# S1C31D50 register map
Vendor: Epson; Series: S1C31D50; File version: 1.00
CPU: CM0PLUS r0p1, little endian, MPU, no FPU, VTOR, 2 interrupt priority bits
Registers are 16-bit, read-write, reset 0x0 unless marked. A register's access mark holds for its fields unless they carry their own. Offsets are from the block's base; [hi:lo] are bit positions; {n}, {i} and the like mark numbered series; 'fields as' and 'values as' point back to an identical list.

## UART3_0 — UART3 channel 0 control
Base 0x00200380
Same registers: UART3_1 0x00200600, UART3_2 0x00200620
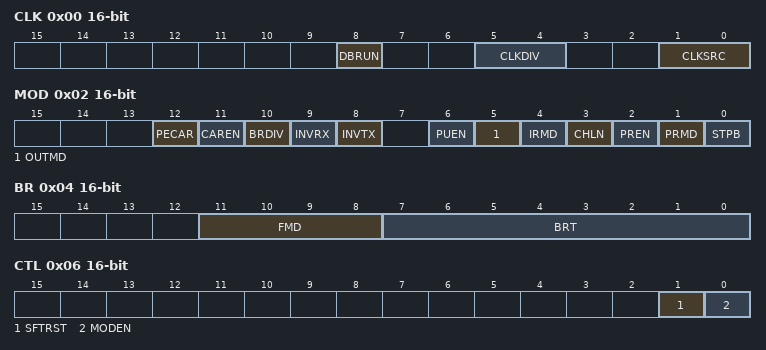
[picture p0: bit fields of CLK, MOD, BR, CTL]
0x00 CLK — Clock Control Register
  [8] DBRUN — Enable clock on debug mode
    0=DISABLE; 1=ENABLE
  [5:4] CLKDIV — Clock division select
  [1:0] CLKSRC — Clock source select
    0=IOSC; 1=OSC1; 2=OSC3; 3=EXOSC
0x02 MOD — Mode Register
  [12] PECAR — Carrier Modulation Period
    0=L_LEVEL (Carrier modulation during L data period); 1=H_LEVEL (Carrier modulation during H data period)
  [11] CAREN — Carrier Modulation Enable
    0=DISABLE (Disable carrier modulation function); 1=ENABLE (Enable carrier modulation function)
  [10] BRDIV — Baud Rate Division ratio
    0=DIV_1_16 (Ratio 1 over 16); 1=DIV_1_4 (Ratio 1 over 4)
  [9] INVRX — Invert receive signal
    0=DISABLE (Disable input inverting function); 1=ENABLE (Enable input inverting function)
  [8] INVTX — Invert transmit signal
    0=DISABLE (Disable output inverting function); 1=ENABLE (Enable output inverting function)
  [6] PUEN — USIN pullup enable
    0=DISABLE (Disable pull-up); 1=ENABLE (Enable pull-up)
  [5] OUTMD — Output mode select
    0=PUSH_PULL (Push-pull output); 1=OPEN_DRAIN (Open-drain output)
  [4] IRMD — IrDA mode select
    0=DISABLE (Disable IrDA interface function); 1=ENABLE (Enable IrDA interface function)
  [3] CHLN — Character length
    0=7_BIT (7 bits); 1=8_BIT (8 bits)
  [2] PREN — Parity enable
    0=DISABLE (Disable parity function); 1=ENABLE (Enable parity function)
  [1] PRMD — Parity mode select
    0=EVEN (Even parity); 1=ODD (Odd parity)
  [0] STPB — Stop bit select
    0=1_BIT; 1=2_BIT (2 bits)
0x04 BR — Baud Rate Register
  [11:8] FMD — Fine mode control
  [7:0] BRT — Baud rate setting
0x06 CTL — Control Register
  [1] SFTRST write-1-sets — Soft reset
    on write: 0=NON (No effect); 1=RESET (Issue software reset) | on read: 0=STOPPED (Software reset has finished (During normal operation)); 1=RUNNING (Software reset is executing)
  [0] MODEN — UART3 enable
    0=DISABLE (Disable UART2 operations (The operating clock is stopped)); 1=ENABLE (Enable UART2 operations (The operating clock is supplied))
0x08 TXD — Transmit Data Register
  [7:0] TXD — Transmit data
0x0A RXD ro — Receive Data Register
  [7:0] RXD — Receive data
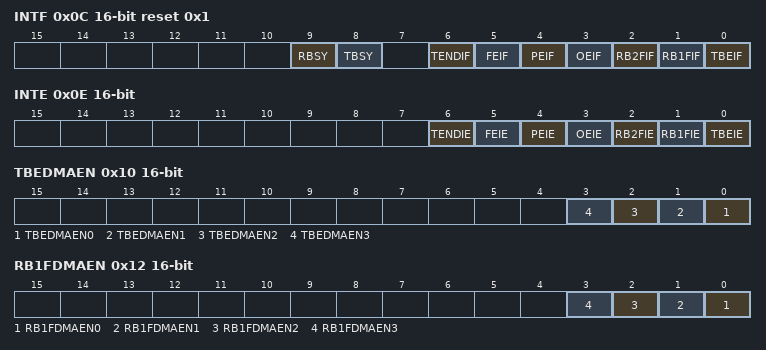
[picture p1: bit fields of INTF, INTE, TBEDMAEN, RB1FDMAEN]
0x0C INTF reset 0x1 — Status and Interrupt Flag Register
  [9] RBSY ro — Receive busy status
    0=IDLE; 1=BUSY (During receiving)
  [8] TBSY ro — Transmit busy status
    0=IDLE; 1=BUSY (During sending)
  [6] TENDIF write-1-clears — End of transmission interrupt flag
    0=NOT_OCCURED (No cause of interrupt occurred); 1=OCCURED (Cause of interrupt occurred)
  [5] FEIF write-1-clears — Framing error interrupt flag (Clear by writing one, or reading UA0RXD register)
    values as TENDIF
  [4] PEIF write-1-clears — Parity error interrupt flag (Clear by writing one, or reading UA0RXD register)
    values as TENDIF
  [3] OEIF write-1-clears — Overrun error interrupt flag
    values as TENDIF
  [2] RB2FIF ro — Receive buffer 2byte full interrupt flag (Clear by reading UA0RXD register)
    values as TENDIF
  [1] RB1FIF ro — Receive buffer 1byte full interrupt flag (Clear by reading UA0RXD register)
    values as TENDIF
  [0] TBEIF ro — Transmit buffer empty interrupt flag (Cleared by writing to UA0TXD register)
    values as TENDIF
0x0E INTE — Interrupt Enable Register
  [all] fields
    0=DISABLE; 1=ENABLE
  [6] TENDIE — End of transmission interrupt enable
  [5] FEIE — Framing error interrupt enable
  [4] PEIE — Parity error interrupt enable
  [3] OEIE — Overrun error interrupt enable
  [2] RB2FIE — Receive buffer 2byte full interrupt enable
  [1] RB1FIE — Receive buffer 1byte full interrupt enable
  [0] TBEIE — Transmit buffer empty interrupt enable
0x10 TBEDMAEN — TBE DMA Enable Register
  [all] fields
    0=DISABLE; 1=ENABLE
  [n] TBEDMAEN{n} (n=0..3) — TBE DMA ch{n} request enable
0x12 RB1FDMAEN — RB1F DMA Enable Register
  [all] fields
    0=DISABLE; 1=ENABLE
  [n] RB1FDMAEN{n} (n=0..3) — RB1F DMA ch{n} request enable
0x14 CAWF — UART carrier waveform register
  [7:0] CRPER — Carrier period
